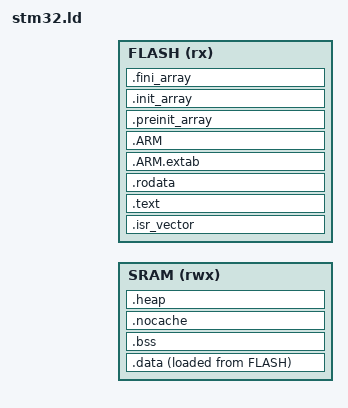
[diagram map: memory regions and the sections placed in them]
/*
 * Copyright (c) 2014-2017 Cesanta Software Limited
 * All rights reserved
 */

ENTRY(Reset_Handler)

_estack = SRAM_BASE_ADDR + SRAM_SIZE;
_init_stack_size = 0x400; /* stack size before FreeRTOS is running */

MEMORY
{
  SRAM (rwx) : ORIGIN = SRAM_BASE_ADDR,  LENGTH = SRAM_SIZE
  FLASH (rx) : ORIGIN = FLASH_BASE_ADDR, LENGTH = FLASH_SIZE
}

/* Define output sections */
SECTIONS
{
  /* The startup code goes first into FLASH */
  .isr_vector :
  {
    . = ALIGN(4);
    KEEP(*(.isr_vector)) /* Startup code */
    . = ALIGN(4);
  } >FLASH

  /* The program code and other data goes into FLASH */
  .text :
  {
    . = ALIGN(4);
    *(.text)           /* .text sections (code) */
    *(.text*)          /* .text* sections (code) */
    *(.glue_7)         /* glue arm to thumb code */
    *(.glue_7t)        /* glue thumb to arm code */
    *(.eh_frame)

    KEEP (*(.init))
    KEEP (*(.fini))

    . = ALIGN(4);
    _etext = .;        /* define a global symbols at end of code */
  } >FLASH

  /* Constant data goes into FLASH */
  .rodata :
  {
    . = ALIGN(4);
    *(.rodata)         /* .rodata sections (constants, strings, etc.) */
    *(.rodata*)        /* .rodata* sections (constants, strings, etc.) */
    . = ALIGN(4);
    *(.fs_bin)         /* Initial filesystem image */
    . = ALIGN(4);
  } >FLASH

  .ARM.extab   : { *(.ARM.extab* .gnu.linkonce.armextab.*) } >FLASH
  .ARM : {
    __exidx_start = .;
    *(.ARM.exidx*)
    __exidx_end = .;
  } >FLASH

  .preinit_array     :
  {
    PROVIDE_HIDDEN (__preinit_array_start = .);
    KEEP (*(.preinit_array*))
    PROVIDE_HIDDEN (__preinit_array_end = .);
  } >FLASH
  .init_array :
  {
    PROVIDE_HIDDEN (__init_array_start = .);
    KEEP (*(SORT(.init_array.*)))
    KEEP (*(.init_array*))
    PROVIDE_HIDDEN (__init_array_end = .);
  } >FLASH
  .fini_array :
  {
    PROVIDE_HIDDEN (__fini_array_start = .);
    KEEP (*(SORT(.fini_array.*)))
    KEEP (*(.fini_array*))
    PROVIDE_HIDDEN (__fini_array_end = .);
  } >FLASH

  /* used by the startup to initialize data */
  _sidata = LOADADDR(.data);

  /* Initialized data sections goes into RAM, load LMA copy after code */
  .data :
  {
    . = ALIGN(4);
    _sdata = .;        /* create a global symbol at data start */
    *(.data)           /* .data sections */
    *(.data*)          /* .data* sections */

    . = ALIGN(4);
    *(.iram .iram.*)   /* code placed in RAM */
    _edata = .;        /* define a global symbol at data end */
  } >SRAM AT> FLASH

  /* Uninitialized data section */
  . = ALIGN(4);
  .bss :
  {
    /* This is used by the startup in order to initialize the .bss secion */
    _sbss = .;         /* define a global symbol at bss start */
    __bss_start__ = _sbss;
    *(.bss)
    *(.bss*)
    *(COMMON)

    . = ALIGN(4);
    _ebss = .;         /* define a global symbol at bss end */
    __bss_end__ = _ebss;
  } >SRAM

  /* For now, max size of no-cache region is 1K */
  .nocache :
  {
    . = ALIGN(NOCACHE_SIZE);
    __nocache_start__ = .;
    *(.nocache)
    . = ALIGN(NOCACHE_SIZE);
    __nocache_end__ = .;
  } >SRAM

  .heap :
  {
    . = ALIGN(8);
    _heap_start = .;
    . = . + (LENGTH(SRAM) - SIZEOF(.data) - SIZEOF(.bss) - SIZEOF(.nocache) - _init_stack_size);
    . = ALIGN(8);
    _heap_end = .;
  } >SRAM

  /* Remove information from the standard libraries */
  /DISCARD/ :
  {
    libc.a ( * )
    libm.a ( * )
    libgcc.a ( * )
  }

  .ARM.attributes 0 : { *(.ARM.attributes) }
}
